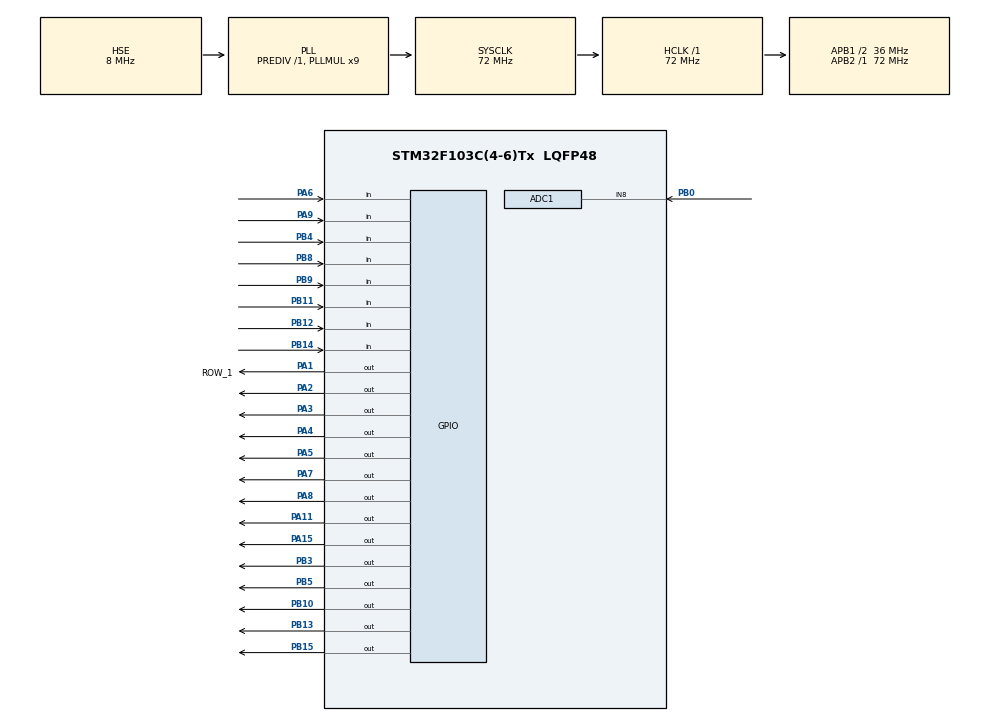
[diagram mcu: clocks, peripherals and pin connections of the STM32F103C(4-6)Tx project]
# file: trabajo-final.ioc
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ADC1.Channel-0\#ChannelRegularConversion=ADC_CHANNEL_8
ADC1.NbrOfConversionFlag=1
ADC1.Rank-0\#ChannelRegularConversion=1
ADC1.SamplingTime-0\#ChannelRegularConversion=ADC_SAMPLETIME_1CYCLE_5
ADC1.master=1
Mcu.Family=STM32F1
Mcu.Name=STM32F103C(4-6)Tx
Mcu.Package=LQFP48
NVIC.ADC1_2_IRQn=true\:0\:0\:false\:false\:true\:true\:true\:true
NVIC.PriorityGroup=NVIC_PRIORITYGROUP_4
PA1.GPIO_Label=ROW_1
PA1.Signal=GPIO_Output
PA11.Signal=GPIO_Output
PA15.Signal=GPIO_Output
PA2.Signal=GPIO_Output
PA3.Signal=GPIO_Output
PA4.Signal=GPIO_Output
PA5.Signal=GPIO_Output
PA6.Signal=GPIO_Input
PA7.Signal=GPIO_Output
PA8.Signal=GPIO_Output
PA9.GPIO_PuPd=GPIO_PULLUP
PA9.Signal=GPIO_Input
PB0.Signal=ADCx_IN8
PB10.Signal=GPIO_Output
PB11.GPIO_PuPd=GPIO_PULLUP
PB11.Signal=GPIO_Input
PB12.GPIO_PuPd=GPIO_PULLUP
PB12.Signal=GPIO_Input
PB13.Signal=GPIO_Output
PB14.GPIO_PuPd=GPIO_PULLUP
PB14.Signal=GPIO_Input
PB15.Signal=GPIO_Output
PB3.Signal=GPIO_Output
PB4.Signal=GPIO_Input
PB5.Signal=GPIO_Output
PB6.Signal=I2C1_SCL
PB7.Signal=I2C1_SDA
PB8.Signal=GPIO_Input
PB9.Signal=GPIO_Input
PC14-OSC32_IN.Mode=LSE-External-Oscillator
PC14-OSC32_IN.Signal=RCC_OSC32_IN
PC15-OSC32_OUT.Mode=LSE-External-Oscillator
PC15-OSC32_OUT.Signal=RCC_OSC32_OUT
PD0-OSC_IN.Mode=HSE-External-Oscillator
PD0-OSC_IN.Signal=RCC_OSC_IN
PD1-OSC_OUT.Mode=HSE-External-Oscillator
PD1-OSC_OUT.Signal=RCC_OSC_OUT
ProjectManager.HeapSize=0x200
ProjectManager.StackSize=0x400
ProjectManager.TargetToolchain=STM32CubeIDE
RCC.ADCPresc=RCC_ADCPCLK2_DIV6
RCC.AHBFreq_Value=72000000
RCC.APB1CLKDivider=RCC_HCLK_DIV2
RCC.APB1Freq_Value=36000000
RCC.APB1TimFreq_Value=72000000
RCC.APB2Freq_Value=72000000
RCC.APB2TimFreq_Value=72000000
RCC.HCLKFreq_Value=72000000
RCC.PLLMUL=RCC_PLL_MUL9
RCC.PLLSourceVirtual=RCC_PLLSOURCE_HSE
RCC.RTCClockSelection=RCC_RTCCLKSOURCE_LSE
RCC.SYSCLKFreq_VALUE=72000000
RCC.SYSCLKSource=RCC_SYSCLKSOURCE_PLLCLK
RCC.USBFreq_Value=72000000
SH.ADCx_IN8.0=ADC1_IN8,IN8
VP_RTC_VS_RTC_Activate.Mode=RTC_Enabled
VP_RTC_VS_RTC_Calendar.Mode=RTC_Calendar
VP_SYS_VS_ND.Mode=No_Debug
board=custom

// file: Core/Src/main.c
/* USER CODE BEGIN Header */
/**
  ******************************************************************************
  * @file           : main.c
  * @brief          : Main program body
  ******************************************************************************
  * @attention
  *
  * Copyright (c) 2025 STMicroelectronics.
  * All rights reserved.
  *
  * This software is licensed under terms that can be found in the LICENSE file
  * in the root directory of this software component.
  * If no LICENSE file comes with this software, it is provided AS-IS.
  *
  ******************************************************************************
  */
/* USER CODE END Header */
#include <system.h>
#include "main.h"

ADC_HandleTypeDef hadc1;

RTC_HandleTypeDef hrtc;

void SystemClock_Config(void);
static void MX_GPIO_Init(void);
static void MX_ADC1_Init(void);
static void MX_RTC_Init(void);

int main(void)
{

  /* MCU Configuration--------------------------------------------------------*/

  /* Reset of all peripherals, Initializes the Flash interface and the Systick. */
  HAL_Init();

  /* Configure the system clock */
  SystemClock_Config();

  /* Initialize all configured peripherals */
  MX_GPIO_Init();
  MX_ADC1_Init();
  MX_RTC_Init();
  /* USER CODE BEGIN 2 */
  lcd_init();
  clock_init(&hrtc);
  temperature_sensor_init(&hadc1);
  alarm_init();

  clock_set_date(20, 12, 25);
  clock_set_time(23, 59, 30);
  clock_update_datetime();

  /* USER CODE END 2 */

  /* Infinite loop */
  /* USER CODE BEGIN WHILE */
  while (1)
  {
	  HAL_Delay(1); //STABILITY

	  state_entry_point(state); //State logic

	  //Check for clock status, error managment
	  if(status_buffer != REST){
		  lcd_clear();
		  lcd_send_string(clock_error_string(status_buffer));
		  HAL_Delay(SHORT_DELAY);

		  status_buffer = REST;
	  }

    /* USER CODE END WHILE */

  }
}

void SystemClock_Config(void)
{
  RCC_OscInitTypeDef RCC_OscInitStruct = {0};
  RCC_ClkInitTypeDef RCC_ClkInitStruct = {0};
  RCC_PeriphCLKInitTypeDef PeriphClkInit = {0};

  /** Initializes the RCC Oscillators according to the specified parameters
  * in the RCC_OscInitTypeDef structure.
  */
  RCC_OscInitStruct.OscillatorType = RCC_OSCILLATORTYPE_HSE|RCC_OSCILLATORTYPE_LSE;
  RCC_OscInitStruct.HSEState = RCC_HSE_ON;
  RCC_OscInitStruct.HSEPredivValue = RCC_HSE_PREDIV_DIV1;
  RCC_OscInitStruct.LSEState = RCC_LSE_ON;
  RCC_OscInitStruct.HSIState = RCC_HSI_ON;
  RCC_OscInitStruct.PLL.PLLState = RCC_PLL_ON;
  RCC_OscInitStruct.PLL.PLLSource = RCC_PLLSOURCE_HSE;
  RCC_OscInitStruct.PLL.PLLMUL = RCC_PLL_MUL9;
  if (HAL_RCC_OscConfig(&RCC_OscInitStruct) != HAL_OK)
  {
    Error_Handler();
  }

  /** Initializes the CPU, AHB and APB buses clocks
  */
  RCC_ClkInitStruct.ClockType = RCC_CLOCKTYPE_HCLK|RCC_CLOCKTYPE_SYSCLK
                              |RCC_CLOCKTYPE_PCLK1|RCC_CLOCKTYPE_PCLK2;
  RCC_ClkInitStruct.SYSCLKSource = RCC_SYSCLKSOURCE_PLLCLK;
  RCC_ClkInitStruct.AHBCLKDivider = RCC_SYSCLK_DIV1;
  RCC_ClkInitStruct.APB1CLKDivider = RCC_HCLK_DIV2;
  RCC_ClkInitStruct.APB2CLKDivider = RCC_HCLK_DIV1;

  if (HAL_RCC_ClockConfig(&RCC_ClkInitStruct, FLASH_LATENCY_2) != HAL_OK)
  {
    Error_Handler();
  }
  PeriphClkInit.PeriphClockSelection = RCC_PERIPHCLK_RTC|RCC_PERIPHCLK_ADC;
  PeriphClkInit.RTCClockSelection = RCC_RTCCLKSOURCE_LSE;
  PeriphClkInit.AdcClockSelection = RCC_ADCPCLK2_DIV6;
  if (HAL_RCCEx_PeriphCLKConfig(&PeriphClkInit) != HAL_OK)
  {
    Error_Handler();
  }
}

static void MX_ADC1_Init(void)
{

  ADC_ChannelConfTypeDef sConfig = {0};

  /** Common config
  */
  hadc1.Instance = ADC1;
  hadc1.Init.ScanConvMode = ADC_SCAN_DISABLE;
  hadc1.Init.ContinuousConvMode = DISABLE;
  hadc1.Init.DiscontinuousConvMode = DISABLE;
  hadc1.Init.ExternalTrigConv = ADC_SOFTWARE_START;
  hadc1.Init.DataAlign = ADC_DATAALIGN_RIGHT;
  hadc1.Init.NbrOfConversion = 1;
  if (HAL_ADC_Init(&hadc1) != HAL_OK)
  {
    Error_Handler();
  }

  /** Configure Regular Channel
  */
  sConfig.Channel = ADC_CHANNEL_8;
  sConfig.Rank = ADC_REGULAR_RANK_1;
  sConfig.SamplingTime = ADC_SAMPLETIME_1CYCLE_5;
  if (HAL_ADC_ConfigChannel(&hadc1, &sConfig) != HAL_OK)
  {
    Error_Handler();
  }

}

static void MX_RTC_Init(void)
{

  RTC_TimeTypeDef sTime = {0};
  RTC_DateTypeDef DateToUpdate = {0};

  /** Initialize RTC Only
  */
  hrtc.Instance = RTC;
  hrtc.Init.AsynchPrediv = RTC_AUTO_1_SECOND;
  hrtc.Init.OutPut = RTC_OUTPUTSOURCE_ALARM;
  if (HAL_RTC_Init(&hrtc) != HAL_OK)
  {
    Error_Handler();
  }

  /** Initialize RTC and set the Time and Date
  */
  sTime.Hours = 0x0;
  sTime.Minutes = 0x0;
  sTime.Seconds = 0x0;

  if (HAL_RTC_SetTime(&hrtc, &sTime, RTC_FORMAT_BCD) != HAL_OK)
  {
    Error_Handler();
  }
  DateToUpdate.WeekDay = RTC_WEEKDAY_MONDAY;
  DateToUpdate.Month = RTC_MONTH_JANUARY;
  DateToUpdate.Date = 0x1;
  DateToUpdate.Year = 0x0;

  if (HAL_RTC_SetDate(&hrtc, &DateToUpdate, RTC_FORMAT_BCD) != HAL_OK)
  {
    Error_Handler();
  }

}

static void MX_GPIO_Init(void)
{
  GPIO_InitTypeDef GPIO_InitStruct = {0};

  /* GPIO Ports Clock Enable */
  __HAL_RCC_GPIOC_CLK_ENABLE();
  __HAL_RCC_GPIOD_CLK_ENABLE();
  __HAL_RCC_GPIOA_CLK_ENABLE();
  __HAL_RCC_GPIOB_CLK_ENABLE();

  /*Configure GPIO pin Output Level */
  HAL_GPIO_WritePin(GPIOA, ROW_1_Pin|GPIO_PIN_2|GPIO_PIN_3|GPIO_PIN_4
                          |GPIO_PIN_5|GPIO_PIN_7|GPIO_PIN_8|GPIO_PIN_11
                          |GPIO_PIN_15, GPIO_PIN_RESET);

  /*Configure GPIO pin Output Level */
  HAL_GPIO_WritePin(GPIOB, GPIO_PIN_10|GPIO_PIN_13|GPIO_PIN_15|GPIO_PIN_3
                          |GPIO_PIN_5, GPIO_PIN_RESET);

  /*Configure GPIO pins : ROW_1_Pin PA2 PA3 PA4
                           PA5 PA7 PA8 PA11
                           PA15 */
  GPIO_InitStruct.Pin = ROW_1_Pin|GPIO_PIN_2|GPIO_PIN_3|GPIO_PIN_4
                          |GPIO_PIN_5|GPIO_PIN_7|GPIO_PIN_8|GPIO_PIN_11
                          |GPIO_PIN_15;
  GPIO_InitStruct.Mode = GPIO_MODE_OUTPUT_PP;
  GPIO_InitStruct.Pull = GPIO_NOPULL;
  GPIO_InitStruct.Speed = GPIO_SPEED_FREQ_LOW;
  HAL_GPIO_Init(GPIOA, &GPIO_InitStruct);

  /*Configure GPIO pin : PA6 */
  GPIO_InitStruct.Pin = GPIO_PIN_6;
  GPIO_InitStruct.Mode = GPIO_MODE_INPUT;
  GPIO_InitStruct.Pull = GPIO_PULLDOWN;
  HAL_GPIO_Init(GPIOA, &GPIO_InitStruct);

  /*Configure GPIO pins : PB10 PB13 PB15 PB3
                           PB5 */
  GPIO_InitStruct.Pin = GPIO_PIN_10|GPIO_PIN_13|GPIO_PIN_15|GPIO_PIN_3
                          |GPIO_PIN_5;
  GPIO_InitStruct.Mode = GPIO_MODE_OUTPUT_PP;
  GPIO_InitStruct.Pull = GPIO_NOPULL;
  GPIO_InitStruct.Speed = GPIO_SPEED_FREQ_LOW;
  HAL_GPIO_Init(GPIOB, &GPIO_InitStruct);

  /*Configure GPIO pins : PB11 PB12 PB14 */
  GPIO_InitStruct.Pin = GPIO_PIN_11|GPIO_PIN_12|GPIO_PIN_14;
  GPIO_InitStruct.Mode = GPIO_MODE_INPUT;
  GPIO_InitStruct.Pull = GPIO_PULLUP;
  HAL_GPIO_Init(GPIOB, &GPIO_InitStruct);

  /*Configure GPIO pin : PA9 */
  GPIO_InitStruct.Pin = GPIO_PIN_9;
  GPIO_InitStruct.Mode = GPIO_MODE_INPUT;
  GPIO_InitStruct.Pull = GPIO_PULLUP;
  HAL_GPIO_Init(GPIOA, &GPIO_InitStruct);

  /*Configure GPIO pins : PB4 PB8 PB9 */
  GPIO_InitStruct.Pin = GPIO_PIN_4|GPIO_PIN_8|GPIO_PIN_9;
  GPIO_InitStruct.Mode = GPIO_MODE_INPUT;
  GPIO_InitStruct.Pull = GPIO_PULLDOWN;
  HAL_GPIO_Init(GPIOB, &GPIO_InitStruct);

  /*Configure GPIO pins : PB6 PB7 */
  GPIO_InitStruct.Pin = GPIO_PIN_6|GPIO_PIN_7;
  GPIO_InitStruct.Mode = GPIO_MODE_AF_OD;
  GPIO_InitStruct.Pull = GPIO_NOPULL;
  GPIO_InitStruct.Speed = GPIO_SPEED_FREQ_HIGH;
  HAL_GPIO_Init(GPIOB, &GPIO_InitStruct);

}

void Error_Handler(void)
{
  __disable_irq();
  while (1)
  {
  }
}
